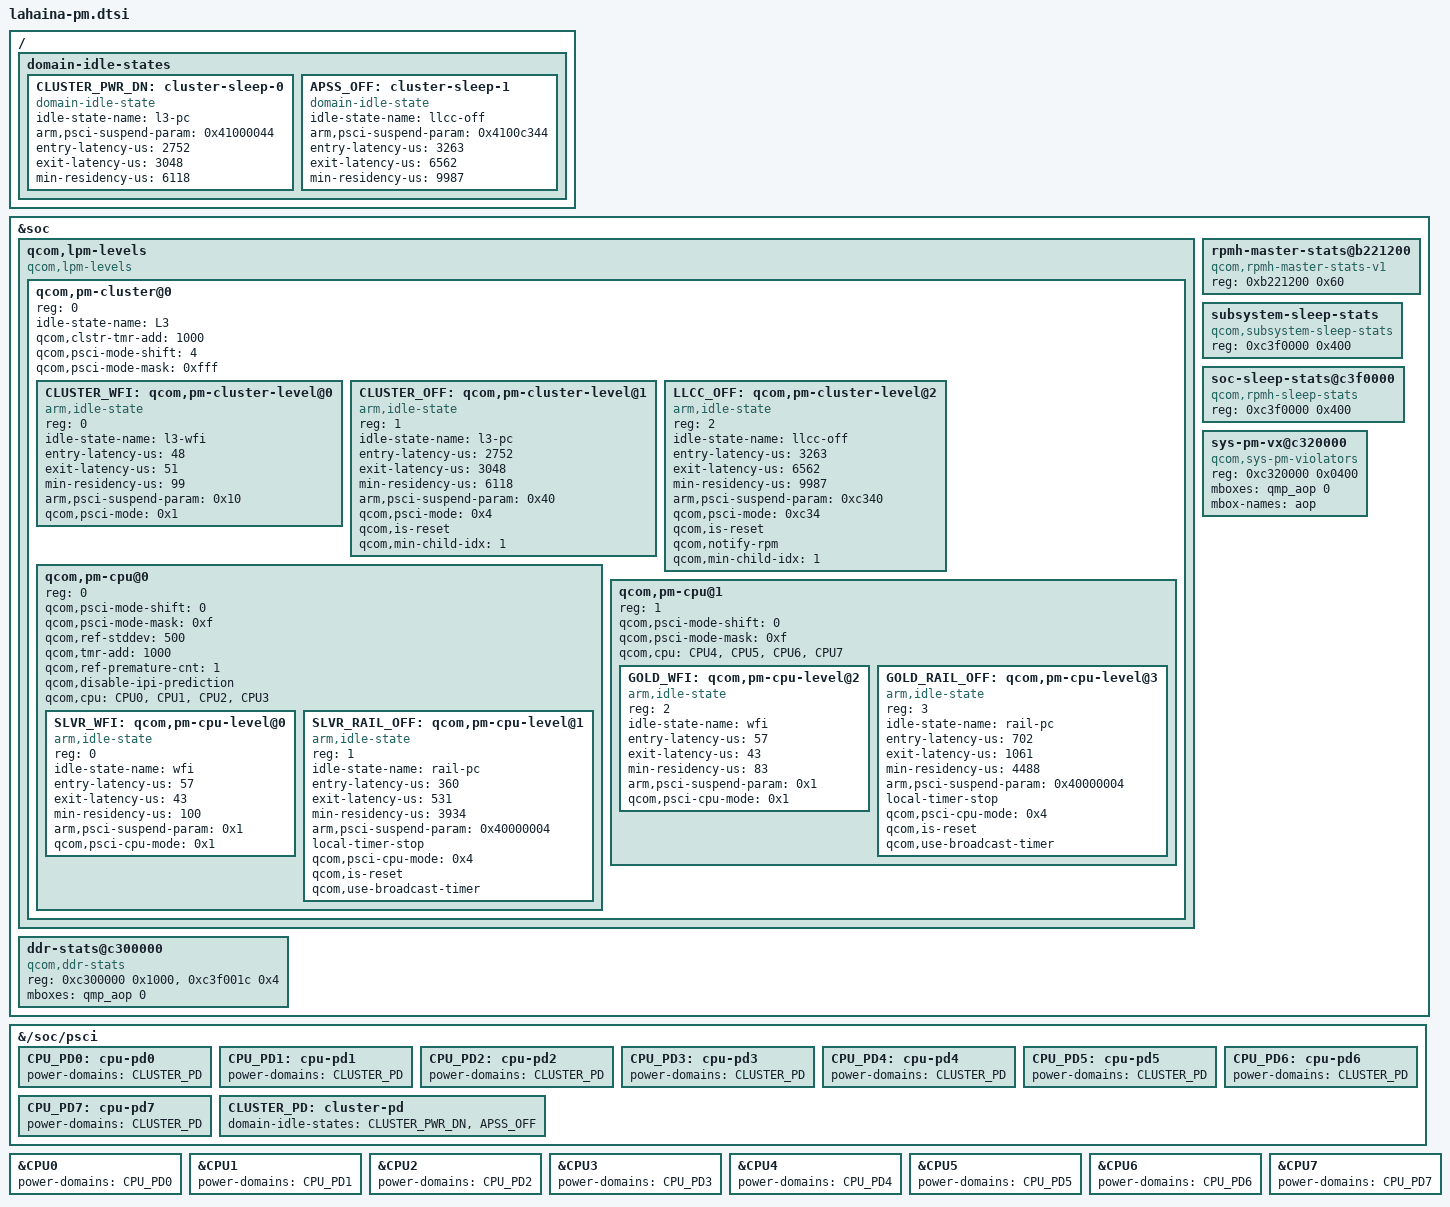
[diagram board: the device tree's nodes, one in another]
&soc {
	qcom,lpm-levels {
		compatible = "qcom,lpm-levels";
		#address-cells = <1>;
		#size-cells = <0>;

		qcom,pm-cluster@0 {
			reg = <0>;
			#address-cells = <1>;
			#size-cells = <0>;
			idle-state-name = "L3";
			qcom,clstr-tmr-add = <1000>;
			qcom,psci-mode-shift = <4>;
			qcom,psci-mode-mask = <0xfff>;

			CLUSTER_WFI: qcom,pm-cluster-level@0 { /* D1 */
				reg = <0>;
				compatible = "arm,idle-state";
				idle-state-name = "l3-wfi";
				entry-latency-us = <48>;
				exit-latency-us = <51>;
				min-residency-us = <99>;
				arm,psci-suspend-param = <0x10>;
				qcom,psci-mode = <0x1>;
			};

			CLUSTER_OFF: qcom,pm-cluster-level@1 { /* D4 */
				reg = <1>;
				compatible = "arm,idle-state";
				idle-state-name = "l3-pc";
				entry-latency-us = <2752>;
				exit-latency-us = <3048>;
				min-residency-us = <6118>;
				arm,psci-suspend-param = <0x40>;
				qcom,psci-mode = <0x4>;
				qcom,is-reset;
				qcom,min-child-idx = <1>;
			};

			LLCC_OFF: qcom,pm-cluster-level@2 { /* AOSS sleep */
				reg = <2>;
				compatible = "arm,idle-state";
				idle-state-name = "llcc-off";
				entry-latency-us = <3263>;
				exit-latency-us = <6562>;
				min-residency-us = <9987>;
				arm,psci-suspend-param = <0xc340>;
				qcom,psci-mode = <0xc34>;
				qcom,is-reset;
				qcom,notify-rpm;
				qcom,min-child-idx = <1>;
			};

			qcom,pm-cpu@0 {
				reg = <0>;
				#address-cells = <1>;
				#size-cells = <0>;
				qcom,psci-mode-shift = <0>;
				qcom,psci-mode-mask = <0xf>;
				qcom,ref-stddev = <500>;
				qcom,tmr-add = <1000>;
				qcom,ref-premature-cnt = <1>;
				qcom,disable-ipi-prediction;
				qcom,cpu = <&CPU0 &CPU1 &CPU2 &CPU3>;

				SLVR_WFI: qcom,pm-cpu-level@0 { /* C1 */
					reg = <0>;
					compatible = "arm,idle-state";
					idle-state-name = "wfi";
					entry-latency-us = <57>;
					exit-latency-us = <43>;
					min-residency-us = <100>;
					arm,psci-suspend-param = <0x1>;
					qcom,psci-cpu-mode = <0x1>;
				};

				SLVR_RAIL_OFF: qcom,pm-cpu-level@1 {  /* C4 */
					reg = <1>;
					compatible = "arm,idle-state";
					idle-state-name = "rail-pc";
					entry-latency-us = <360>;
					exit-latency-us = <531>;
					min-residency-us = <3934>;
					arm,psci-suspend-param = <0x40000004>;
					local-timer-stop;
					qcom,psci-cpu-mode = <0x4>;
					qcom,is-reset;
					qcom,use-broadcast-timer;
				};
			};

			qcom,pm-cpu@1 {
				reg = <1>;
				#address-cells = <1>;
				#size-cells = <0>;
				qcom,psci-mode-shift = <0>;
				qcom,psci-mode-mask = <0xf>;
				qcom,cpu = <&CPU4 &CPU5 &CPU6 &CPU7>;

				GOLD_WFI: qcom,pm-cpu-level@2 { /* C1 */
					reg = <2>;
					compatible = "arm,idle-state";
					idle-state-name = "wfi";
					entry-latency-us = <57>;
					exit-latency-us = <43>;
					min-residency-us = <83>;
					arm,psci-suspend-param = <0x1>;
					qcom,psci-cpu-mode = <0x1>;
				};

				GOLD_RAIL_OFF: qcom,pm-cpu-level@3 {  /* C4 */
					reg = <3>;
					compatible = "arm,idle-state";
					idle-state-name = "rail-pc";
					entry-latency-us = <702>;
					exit-latency-us = <1061>;
					min-residency-us = <4488>;
					arm,psci-suspend-param = <0x40000004>;
					local-timer-stop;
					qcom,psci-cpu-mode = <0x4>;
					qcom,is-reset;
					qcom,use-broadcast-timer;
				};
			};
		};
	};

	rpmh-master-stats@b221200 {
		compatible = "qcom,rpmh-master-stats-v1";
		reg = <0xb221200 0x60>;
	};

	subsystem-sleep-stats {
		compatible = "qcom,subsystem-sleep-stats";
		reg = <0xc3f0000 0x400>;
	};

	soc-sleep-stats@c3f0000 {
		compatible = "qcom,rpmh-sleep-stats";
		reg = <0xc3f0000 0x400>;
	};

	ddr-stats@c300000 {
		compatible = "qcom,ddr-stats";
		reg = <0xc300000 0x1000>, <0xc3f001c 0x4>;
		reg-names = "phys_addr_base", "offset_addr";
		mboxes = <&qmp_aop 0>;
	};

	sys-pm-vx@c320000 {
		compatible = "qcom,sys-pm-violators", "qcom,sys-pm-lahaina";
		reg = <0xc320000 0x0400>;
		mboxes = <&qmp_aop 0>;
		mbox-names = "aop";
	};
};

/*
 * The same cluster states for PSCI OSI power domains (cpuidle-psci): the
 * suspend params are the composite state IDs that lpm-levels builds above
 * (CPU rail-pc 0x40000004 + affinity level 1 + cluster mode << 4).
 */
/ {
	domain-idle-states {
		CLUSTER_PWR_DN: cluster-sleep-0 {
			compatible = "domain-idle-state";
			idle-state-name = "l3-pc";
			arm,psci-suspend-param = <0x41000044>;
			entry-latency-us = <2752>;
			exit-latency-us = <3048>;
			min-residency-us = <6118>;
		};

		APSS_OFF: cluster-sleep-1 {
			compatible = "domain-idle-state";
			idle-state-name = "llcc-off";
			arm,psci-suspend-param = <0x4100c344>;
			entry-latency-us = <3263>;
			exit-latency-us = <6562>;
			min-residency-us = <9987>;
		};
	};
};

&{/soc/psci} {
	CPU_PD0: cpu-pd0 {
		#power-domain-cells = <0>;
		power-domains = <&CLUSTER_PD>;
	};

	CPU_PD1: cpu-pd1 {
		#power-domain-cells = <0>;
		power-domains = <&CLUSTER_PD>;
	};

	CPU_PD2: cpu-pd2 {
		#power-domain-cells = <0>;
		power-domains = <&CLUSTER_PD>;
	};

	CPU_PD3: cpu-pd3 {
		#power-domain-cells = <0>;
		power-domains = <&CLUSTER_PD>;
	};

	CPU_PD4: cpu-pd4 {
		#power-domain-cells = <0>;
		power-domains = <&CLUSTER_PD>;
	};

	CPU_PD5: cpu-pd5 {
		#power-domain-cells = <0>;
		power-domains = <&CLUSTER_PD>;
	};

	CPU_PD6: cpu-pd6 {
		#power-domain-cells = <0>;
		power-domains = <&CLUSTER_PD>;
	};

	CPU_PD7: cpu-pd7 {
		#power-domain-cells = <0>;
		power-domains = <&CLUSTER_PD>;
	};

	CLUSTER_PD: cluster-pd {
		#power-domain-cells = <0>;
		domain-idle-states = <&CLUSTER_PWR_DN &APSS_OFF>;
	};
};

&CPU0 {
	power-domains = <&CPU_PD0>;
	power-domain-names = "psci";
};

&CPU1 {
	power-domains = <&CPU_PD1>;
	power-domain-names = "psci";
};

&CPU2 {
	power-domains = <&CPU_PD2>;
	power-domain-names = "psci";
};

&CPU3 {
	power-domains = <&CPU_PD3>;
	power-domain-names = "psci";
};

&CPU4 {
	power-domains = <&CPU_PD4>;
	power-domain-names = "psci";
};

&CPU5 {
	power-domains = <&CPU_PD5>;
	power-domain-names = "psci";
};

&CPU6 {
	power-domains = <&CPU_PD6>;
	power-domain-names = "psci";
};

&CPU7 {
	power-domains = <&CPU_PD7>;
	power-domain-names = "psci";
};
